# TC35680 register map
Vendor: Toshiba Electronic Devices and Storage Corporation; File version: 0.1
CPU: CM0 r0p0, little endian, no MPU, no FPU, 4 interrupt priority bits
Registers are 32-bit, read-write, no defined reset value unless marked. A register's access mark holds for its fields unless they carry their own. Offsets are from the block's base; [hi:lo] are bit positions; {n}, {i} and the like mark numbered series.

## CLOCK — Clock Supply for SPI and PWM
Base 0x4004C000
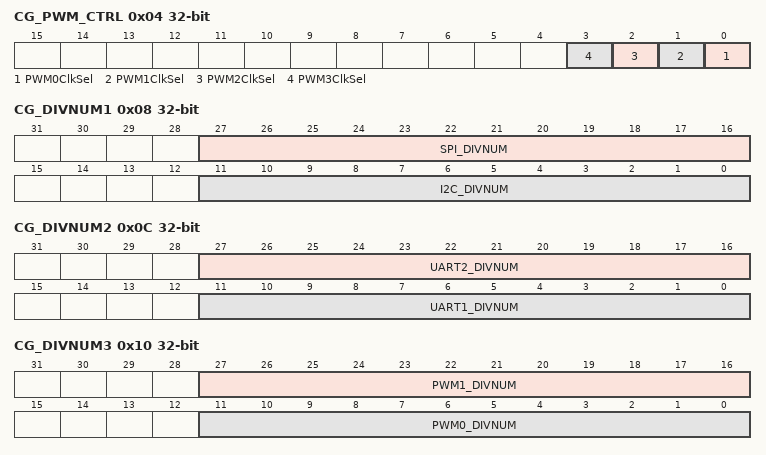
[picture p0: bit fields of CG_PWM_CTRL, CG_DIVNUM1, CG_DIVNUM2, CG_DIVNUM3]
0x04 CG_PWM_CTRL — PWM clock mode set
  [n] PWM{n}ClkSel (n=0..3) — Select PWM{n} clock. 1: MAX 13 MHz (This division ratio can be changed in CG_DIVNUM4). 0: 32 kHz. Please set disable to PWM{n}SlpClkEn and PWM{n}ClkEn before changing this register.
0x08 CG_DIVNUM1 — Division ratio for I2C and SPI
  [27:16] SPI_DIVNUM — Division ratio of 32MHz clock to generate SPI1 clock.
  [11:0] I2C_DIVNUM — Division ratio of 32MHz clock to generate I2C1 clock.
0x0C CG_DIVNUM2 — Division ratio for UART1 and UART2
  [27:16] UART2_DIVNUM — Division ratio of 32MHz clock to generate UART2 clock.
  [11:0] UART1_DIVNUM — Division ratio of 32MHz clock to generate UART1 clock.
0x10 CG_DIVNUM3 — Division ratio for PWM1 and PWM0 config
  [27:16] PWM1_DIVNUM — Division ratio of 32MHz clock to generate PWM1 clock. PWM1 clock ON/OFF can be set on CG_CLK_CTRL2 register. This value can be changed regardless of the clock ON/OFF. However, the output clock may be unstable right after the change of this register. division ratio = (this value + 1) * 2. default value is 0x000 (Divided by 2)
  [11:0] PWM0_DIVNUM — Division ratio of 32MHz clock to generate PWM0 clock. PWM0 clock ON/OFF can be set on CG_CLK_CTRL2 register. This value can be changed regardless of the clock ON/OFF. However, the output clock may be unstable right after the change of this register. division ratio = (this value + 1) * 2. default value is 0x000 (Divided by 2)
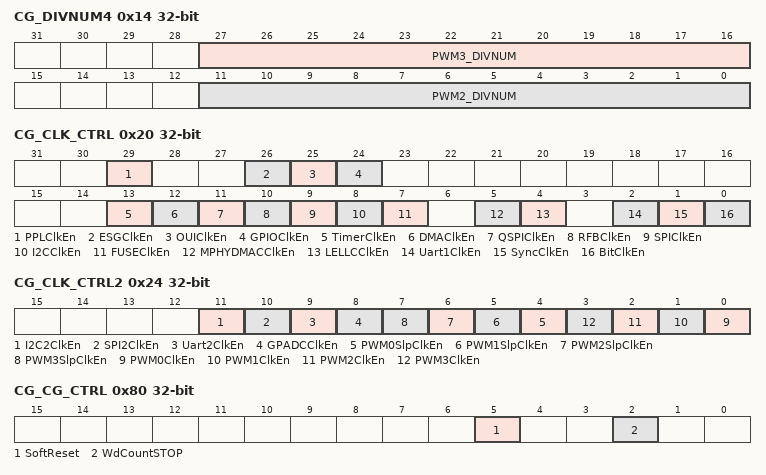
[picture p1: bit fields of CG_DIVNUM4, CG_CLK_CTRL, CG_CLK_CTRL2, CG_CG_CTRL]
0x14 CG_DIVNUM4 — Division ratio for PWM3 and PWM2 config
  [27:16] PWM3_DIVNUM — Division ratio of 32MHz clock to generate PWM3 clock. PWM3 clock ON/OFF can be set on CG_CLK_CTRL2 register. This value can be changed regardless of the clock ON/OFF. However, the output clock may be unstable right after the change of this register. division ratio = (this value + 1) * 2. default value is 0x000 (Divided by 2)
  [11:0] PWM2_DIVNUM — Division ratio of 32MHz clock to generate PWM2 clock. PWM2 clock ON/OFF can be set on CG_CLK_CTRL2 register. This value can be changed regardless of the clock ON/OFF. However, the output clock may be unstable right after the change of this register. division ratio = (this value + 1) * 2. default value is 0x000 (Divided by 2)
0x18 CG_DIVNUM5 — Division ratio for GPADC config
  [8:0] GPADC_DIVNUM — Division ratio of 32MHz clock to generate GPADC clock. frequency divider = (value+1)*2
0x20 CG_CLK_CTRL — SPI Clock control
  [29] PPLClkEn — Enable PPL Clock
  [26] ESGClkEn — Enable ESG Clock
  [25] OUIClkEn — Enable OIU Clock
  [24] GPIOClkEn — Enable GPIO Clock
  [13] TimerClkEn — Enable Timer Clock
  [12] DMAClkEn — ENable DMA Clock
  [11] QSPIClkEn — Enable QSPI Clock
  [10] RFBClkEn — Enable RFB Clock Enable
  [9] SPIClkEn — Enable SPI clock (R/W) 1: Enable clock 0: Disable clock (default)
  [8] I2CClkEn — Enable I2C Clock
  [7] FUSEClkEn — Enable FUSE Clock
  [5] MPHYDMACClkEn — Enable MPHDMAC Clock
  [4] LELLCClkEn — Enable LELLC Clock
  [2] Uart1ClkEn — Enable UART1 Clock
  [1] SyncClkEn — Enable Sync Clock
  [0] BitClkEn — Enable Bit Clock
0x24 CG_CLK_CTRL2 — PWM Clock Control
  [11] I2C2ClkEn — Enable I2C2 Clock
  [10] SPI2ClkEn — Enable SPI2 Clock
  [9] Uart2ClkEn — Enable UART2 Clock
  [8] GPADCClkEn — Enable GPADC Clock
  [n+4] PWM{n}SlpClkEn (n=0..3) — Enable PWM ch {n} slow clock (R/W). 1: Enable clock. 0: Disable clock (default)
  [n] PWM{n}ClkEn (n=0..3) — Enable PWM ch {n} fast clock (R/W). 1: Enable clock. 0: Disable clock (default)
0x80 CG_CG_CTRL — ckgn config register
  [5] SoftReset — Soft-Reset control 1: Soft-Reset 0: No change
  [2] WdCountSTOP — Start or stop WDT counter. 1: Stop counter. 0: Start counter. When set 1, WDT counter suspends. When set 0, WDT counter resumes. During the system state is low power mode, WDT does not count.
0xA0 CG_WD_INIT — Watchdog initial register
  [20:0] WDINIT — Set initial value of WDT counter. This value can be set from 0x1(30.5 micro seconds) to 0x1FFFFF.(64 seconds). Setting time is calculated as below: setting time = (this value) * 30.5 micro seconds. When you update this value, please wait for more than 2 clocks of SleepClk(32kHz clock) since the previous change. When the system wakes up from low power mode, WDT counter is set this value.
0xA4 CG_WD_CURNT — Watchdog current register
  [20:0] WDTCURNT — Watchdog current value. When the system wakes up from low power mode, this value becomes WDINIT value.
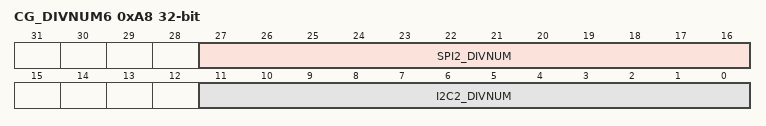
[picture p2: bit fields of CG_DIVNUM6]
0xA8 CG_DIVNUM6 — Division ratio for I2C2 and SPI2
  [27:16] SPI2_DIVNUM — Division ratio of 32MHz clock to generate SPI2 clock.
  [11:0] I2C2_DIVNUM — Division ratio of 32MHz clock to generate I2C2 clock.
